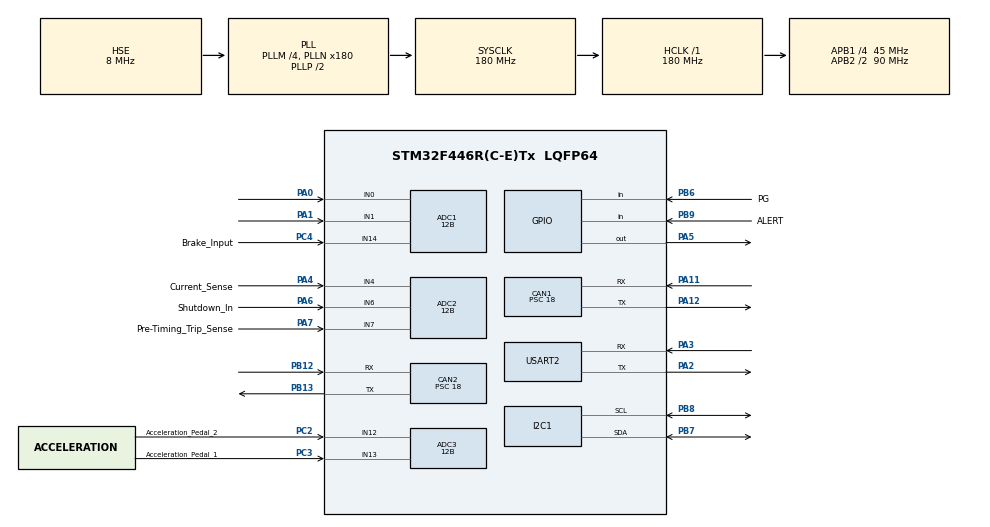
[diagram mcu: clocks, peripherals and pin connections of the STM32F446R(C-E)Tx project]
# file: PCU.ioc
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ADC1.Channel-0\#ChannelRegularConversion=ADC_CHANNEL_0
ADC1.Channel-1\#ChannelRegularConversion=ADC_CHANNEL_1
ADC1.Channel-2\#ChannelRegularConversion=ADC_CHANNEL_14
ADC1.ClockPrescaler=ADC_CLOCK_SYNC_PCLK_DIV4
ADC1.ContinuousConvMode=DISABLE
ADC1.DMAContinuousRequests=ENABLE
ADC1.DataAlign=ADC_DATAALIGN_RIGHT
ADC1.DiscontinuousConvMode=DISABLE
ADC1.EOCSelection=ADC_EOC_SEQ_CONV
ADC1.EnableAnalogWatchDog=false
ADC1.ExternalTrigConv=ADC_EXTERNALTRIGCONV_T2_TRGO
ADC1.ExternalTrigConvEdge=ADC_EXTERNALTRIGCONVEDGE_RISING
ADC1.NbrOfConversion=3
ADC1.NbrOfConversionFlag=1
ADC1.Rank-0\#ChannelRegularConversion=1
ADC1.Rank-1\#ChannelRegularConversion=2
ADC1.Rank-2\#ChannelRegularConversion=3
ADC1.Resolution=ADC_RESOLUTION_12B
ADC1.SamplingTime-0\#ChannelRegularConversion=ADC_SAMPLETIME_15CYCLES
ADC1.SamplingTime-1\#ChannelRegularConversion=ADC_SAMPLETIME_15CYCLES
ADC1.SamplingTime-2\#ChannelRegularConversion=ADC_SAMPLETIME_15CYCLES
ADC1.ScanConvMode=ENABLE
ADC1.master=1
ADC2.Channel-0\#ChannelRegularConversion=ADC_CHANNEL_4
ADC2.Channel-1\#ChannelRegularConversion=ADC_CHANNEL_6
ADC2.Channel-2\#ChannelRegularConversion=ADC_CHANNEL_7
ADC2.ClockPrescaler=ADC_CLOCK_SYNC_PCLK_DIV4
ADC2.ContinuousConvMode=DISABLE
ADC2.DMAContinuousRequests=ENABLE
ADC2.DataAlign=ADC_DATAALIGN_RIGHT
ADC2.DiscontinuousConvMode=DISABLE
ADC2.EOCSelection=ADC_EOC_SEQ_CONV
ADC2.EnableAnalogWatchDog=false
ADC2.ExternalTrigConv=ADC_EXTERNALTRIGCONV_T2_TRGO
ADC2.ExternalTrigConvEdge=ADC_EXTERNALTRIGCONVEDGE_RISING
ADC2.NbrOfConversion=3
ADC2.NbrOfConversionFlag=1
ADC2.Rank-0\#ChannelRegularConversion=1
ADC2.Rank-1\#ChannelRegularConversion=2
ADC2.Rank-2\#ChannelRegularConversion=3
ADC2.Resolution=ADC_RESOLUTION_12B
ADC2.SamplingTime-0\#ChannelRegularConversion=ADC_SAMPLETIME_15CYCLES
ADC2.SamplingTime-1\#ChannelRegularConversion=ADC_SAMPLETIME_15CYCLES
ADC2.SamplingTime-2\#ChannelRegularConversion=ADC_SAMPLETIME_15CYCLES
ADC2.ScanConvMode=ENABLE
ADC3.Channel-0\#ChannelRegularConversion=ADC_CHANNEL_1
ADC3.Channel-1\#ChannelRegularConversion=ADC_CHANNEL_0
ADC3.Channel-2\#ChannelRegularConversion=ADC_CHANNEL_12
ADC3.Channel-3\#ChannelRegularConversion=ADC_CHANNEL_13
ADC3.ClockPrescaler=ADC_CLOCK_SYNC_PCLK_DIV4
ADC3.ContinuousConvMode=DISABLE
ADC3.DMAContinuousRequests=ENABLE
ADC3.DataAlign=ADC_DATAALIGN_RIGHT
ADC3.DiscontinuousConvMode=DISABLE
ADC3.EOCSelection=ADC_EOC_SEQ_CONV
ADC3.EnableAnalogWatchDog=false
ADC3.ExternalTrigConv=ADC_EXTERNALTRIGCONV_T2_TRGO
ADC3.ExternalTrigConvEdge=ADC_EXTERNALTRIGCONVEDGE_RISING
ADC3.NbrOfConversion=4
ADC3.NbrOfConversionFlag=1
ADC3.Rank-0\#ChannelRegularConversion=1
ADC3.Rank-1\#ChannelRegularConversion=2
ADC3.Rank-2\#ChannelRegularConversion=3
ADC3.Rank-3\#ChannelRegularConversion=4
ADC3.Resolution=ADC_RESOLUTION_12B
ADC3.SamplingTime-0\#ChannelRegularConversion=ADC_SAMPLETIME_15CYCLES
ADC3.SamplingTime-1\#ChannelRegularConversion=ADC_SAMPLETIME_15CYCLES
ADC3.SamplingTime-2\#ChannelRegularConversion=ADC_SAMPLETIME_15CYCLES
ADC3.SamplingTime-3\#ChannelRegularConversion=ADC_SAMPLETIME_15CYCLES
ADC3.ScanConvMode=ENABLE
CAN1.BS1=CAN_BS1_3TQ
CAN1.CalculateBaudRate=500000
CAN1.CalculateTimeBit=2000
CAN1.CalculateTimeQuantum=400.0
CAN1.Mode=CAN_MODE_NORMAL
CAN1.Prescaler=18
CAN2.BS1=CAN_BS1_3TQ
CAN2.CalculateBaudRate=500000
CAN2.CalculateTimeBit=2000
CAN2.CalculateTimeQuantum=400.0
CAN2.Mode=CAN_MODE_NORMAL
CAN2.Prescaler=18
Dma.ADC1.0.Direction=DMA_PERIPH_TO_MEMORY
Dma.ADC1.0.FIFOMode=DMA_FIFOMODE_DISABLE
Dma.ADC1.0.Instance=DMA2_Stream0
Dma.ADC1.0.MemDataAlignment=DMA_MDATAALIGN_HALFWORD
Dma.ADC1.0.MemInc=DMA_MINC_ENABLE
Dma.ADC1.0.Mode=DMA_CIRCULAR
Dma.ADC1.0.PeriphDataAlignment=DMA_PDATAALIGN_HALFWORD
Dma.ADC1.0.PeriphInc=DMA_PINC_DISABLE
Dma.ADC1.0.Priority=DMA_PRIORITY_HIGH
Dma.ADC2.1.Direction=DMA_PERIPH_TO_MEMORY
Dma.ADC2.1.FIFOMode=DMA_FIFOMODE_DISABLE
Dma.ADC2.1.Instance=DMA2_Stream2
Dma.ADC2.1.MemDataAlignment=DMA_MDATAALIGN_HALFWORD
Dma.ADC2.1.MemInc=DMA_MINC_ENABLE
Dma.ADC2.1.Mode=DMA_CIRCULAR
Dma.ADC2.1.PeriphDataAlignment=DMA_PDATAALIGN_HALFWORD
Dma.ADC2.1.PeriphInc=DMA_PINC_DISABLE
Dma.ADC2.1.Priority=DMA_PRIORITY_HIGH
Dma.ADC3.2.Direction=DMA_PERIPH_TO_MEMORY
Dma.ADC3.2.FIFOMode=DMA_FIFOMODE_DISABLE
Dma.ADC3.2.Instance=DMA2_Stream1
Dma.ADC3.2.MemDataAlignment=DMA_MDATAALIGN_HALFWORD
Dma.ADC3.2.MemInc=DMA_MINC_ENABLE
Dma.ADC3.2.Mode=DMA_CIRCULAR
Dma.ADC3.2.PeriphDataAlignment=DMA_PDATAALIGN_HALFWORD
Dma.ADC3.2.PeriphInc=DMA_PINC_DISABLE
Dma.ADC3.2.Priority=DMA_PRIORITY_HIGH
Dma.Request0=ADC1
Dma.Request1=ADC2
Dma.Request2=ADC3
Dma.Request3=USART2_TX
Dma.Request4=USART2_RX
Dma.USART2_RX.4.Direction=DMA_PERIPH_TO_MEMORY
Dma.USART2_RX.4.FIFOMode=DMA_FIFOMODE_DISABLE
Dma.USART2_RX.4.Instance=DMA1_Stream5
Dma.USART2_RX.4.MemDataAlignment=DMA_MDATAALIGN_BYTE
Dma.USART2_RX.4.MemInc=DMA_MINC_ENABLE
Dma.USART2_RX.4.Mode=DMA_CIRCULAR
Dma.USART2_RX.4.PeriphDataAlignment=DMA_PDATAALIGN_BYTE
Dma.USART2_RX.4.PeriphInc=DMA_PINC_DISABLE
Dma.USART2_RX.4.Priority=DMA_PRIORITY_LOW
Dma.USART2_TX.3.Direction=DMA_MEMORY_TO_PERIPH
Dma.USART2_TX.3.FIFOMode=DMA_FIFOMODE_DISABLE
Dma.USART2_TX.3.Instance=DMA1_Stream6
Dma.USART2_TX.3.MemDataAlignment=DMA_MDATAALIGN_BYTE
Dma.USART2_TX.3.MemInc=DMA_MINC_ENABLE
Dma.USART2_TX.3.Mode=DMA_NORMAL
Dma.USART2_TX.3.PeriphDataAlignment=DMA_PDATAALIGN_BYTE
Dma.USART2_TX.3.PeriphInc=DMA_PINC_DISABLE
Dma.USART2_TX.3.Priority=DMA_PRIORITY_LOW
FREERTOS.CountingSemaphores01=canTxMailboxSem,3,Dynamic,NULL,3
FREERTOS.Mutexes01=canTxMutex,Dynamic,NULL,Available;i2cMutex,Dynamic,NULL,Available;canRxMutex,Dynamic,NULL,Available;logMutex,Dynamic,NULL,Available;uartTxMutex,Dynamic,NULL,Available
FREERTOS.Queues01=canTxQueue,16,FEB_CAN_Message_t,0,Dynamic,NULL,NULL;canRxQueue,32,FEB_CAN_Message_t,0,Dynamic,NULL,NULL;uartRxQueue,8,FEB_UART_RxQueueMsg_t,0,Dynamic,NULL,NULL
FREERTOS.Tasks01=pcuTask,24,512,StartPCUTask,As weak,NULL,Dynamic,NULL,NULL;uartRxTask,24,512,StartUartRxTask,As weak,NULL,Dynamic,NULL,NULL;canRxTask,40,1024,StartCanRxTask,As weak,NULL,Dynamic,NULL,NULL;canTxTask,40,1024,StartCanTxTask,As weak,NULL,Dynamic,NULL,NULL;canPubTask,40,512,StartCanPubTask,As weak,NULL,Dynamic,NULL,NULL
FREERTOS.configTOTAL_HEAP_SIZE=32768
Mcu.Family=STM32F4
Mcu.Name=STM32F446R(C-E)Tx
Mcu.Package=LQFP64
NVIC.ADC_IRQn=true\:5\:0\:false\:false\:true\:true\:true\:true\:true
NVIC.CAN1_RX0_IRQn=true\:5\:0\:false\:false\:true\:true\:true\:true\:true
NVIC.CAN1_RX1_IRQn=true\:5\:0\:false\:false\:true\:true\:true\:true\:true
NVIC.CAN1_SCE_IRQn=true\:5\:0\:false\:false\:true\:true\:true\:true\:true
NVIC.CAN1_TX_IRQn=true\:5\:0\:false\:false\:true\:true\:true\:true\:true
NVIC.CAN2_RX0_IRQn=true\:5\:0\:false\:false\:true\:true\:true\:true\:true
NVIC.CAN2_RX1_IRQn=true\:5\:0\:false\:false\:true\:true\:true\:true\:true
NVIC.CAN2_SCE_IRQn=true\:5\:0\:false\:false\:true\:true\:true\:true\:true
NVIC.CAN2_TX_IRQn=true\:5\:0\:false\:false\:true\:true\:true\:true\:true
NVIC.DMA1_Stream5_IRQn=true\:5\:0\:false\:false\:true\:true\:false\:true\:true
NVIC.DMA1_Stream6_IRQn=true\:5\:0\:false\:false\:true\:true\:false\:true\:true
NVIC.DMA2_Stream0_IRQn=true\:5\:0\:false\:false\:true\:true\:true\:true\:true
NVIC.DMA2_Stream1_IRQn=true\:5\:0\:false\:false\:true\:true\:true\:true\:true
NVIC.DMA2_Stream2_IRQn=true\:5\:0\:false\:false\:true\:true\:true\:true\:true
NVIC.PriorityGroup=NVIC_PRIORITYGROUP_4
NVIC.TIM1_UP_TIM10_IRQn=true\:5\:0\:false\:false\:true\:true\:true\:true\:true
NVIC.USART2_IRQn=true\:5\:0\:false\:false\:true\:true\:true\:true\:true
PA0-WKUP.Signal=ADCx_IN0
PA1.Signal=ADCx_IN1
PA11.Mode=CAN_Activate
PA11.Signal=CAN1_RX
PA12.Mode=CAN_Activate
PA12.Signal=CAN1_TX
PA13.Mode=JTAG_5_pins
PA13.Signal=SYS_JTMS-SWDIO
PA14.Mode=JTAG_5_pins
PA14.Signal=SYS_JTCK-SWCLK
PA15.Mode=JTAG_5_pins
PA15.Signal=SYS_JTDI
PA2.Mode=Asynchronous
PA2.Signal=USART2_TX
PA3.Mode=Asynchronous
PA3.Signal=USART2_RX
PA4.GPIO_Label=Current_Sense
PA4.Signal=ADCx_IN4
PA5.Signal=GPIO_Output
PA6.GPIO_Label=Shutdown_In
PA6.Signal=ADCx_IN6
PA7.GPIO_Label=Pre-Timing_Trip_Sense
PA7.Signal=ADCx_IN7
PB12.Mode=CAN_Activate
PB12.Signal=CAN2_RX
PB13.Mode=CAN_Activate
PB13.Signal=CAN2_TX
PB3.Mode=JTAG_5_pins
PB3.Signal=SYS_JTDO-SWO
PB4.Mode=JTAG_5_pins
PB4.Signal=SYS_JTRST
PB6.GPIO_Label=PG
PB6.Signal=GPIO_Input
PB7.Mode=I2C
PB7.Signal=I2C1_SDA
PB8.Mode=I2C
PB8.Signal=I2C1_SCL
PB9.GPIO_Label=ALERT
PB9.Signal=GPIO_Input
PC0.GPIO_Label=BSPD_Indicator
PC0.Signal=ADCx_IN10
PC1.GPIO_Label=BSPD_Reset
PC1.Signal=ADCx_IN11
PC2.GPIO_Label=Acceleration_Pedal_2
PC2.Signal=ADCx_IN12
PC3.GPIO_Label=Acceleration_Pedal_1
PC3.Signal=ADCx_IN13
PC4.GPIO_Label=Brake_Input
PC4.Signal=ADCx_IN14
PH0-OSC_IN.Mode=HSE-External-Oscillator
PH0-OSC_IN.Signal=RCC_OSC_IN
PH1-OSC_OUT.Mode=HSE-External-Oscillator
PH1-OSC_OUT.Signal=RCC_OSC_OUT
ProjectManager.HeapSize=0x200
ProjectManager.StackSize=0x400
ProjectManager.TargetToolchain=CMake
RCC.AHBFreq_Value=180000000
RCC.APB1CLKDivider=RCC_HCLK_DIV4
RCC.APB1Freq_Value=45000000
RCC.APB1TimFreq_Value=90000000
RCC.APB2CLKDivider=RCC_HCLK_DIV2
RCC.APB2Freq_Value=90000000
RCC.APB2TimFreq_Value=180000000
RCC.CortexFreq_Value=180000000
RCC.HCLKFreq_Value=180000000
RCC.HSE_VALUE=8000000
RCC.PLLM=4
RCC.PLLN=180
RCC.PLLSourceVirtual=RCC_PLLSOURCE_HSE
RCC.SYSCLKFreq_VALUE=180000000
RCC.SYSCLKSource=RCC_SYSCLKSOURCE_PLLCLK
RCC.USBFreq_Value=180000000
RCC.VCOOutputFreq_Value=360000000
SH.ADCx_IN0.0=ADC1_IN0,IN0
SH.ADCx_IN0.1=ADC3_IN0,IN0
SH.ADCx_IN1.0=ADC1_IN1,IN1
SH.ADCx_IN1.1=ADC3_IN1,IN1
SH.ADCx_IN10.0=ADC3_IN10
SH.ADCx_IN11.0=ADC3_IN11
SH.ADCx_IN12.0=ADC3_IN12,IN12
SH.ADCx_IN13.0=ADC3_IN13,IN13
SH.ADCx_IN14.0=ADC1_IN14,IN14
SH.ADCx_IN4.0=ADC2_IN4,IN4
SH.ADCx_IN6.0=ADC2_IN6,IN6
SH.ADCx_IN7.0=ADC2_IN7,IN7
TIM1.AutoReloadPreload=TIM_AUTORELOAD_PRELOAD_ENABLE
TIM1.Period=1000
TIM1.Prescaler=180
TIM2.AutoReloadPreload=TIM_AUTORELOAD_PRELOAD_ENABLE
TIM2.Period=99
TIM2.Prescaler=89
TIM2.TIM_MasterOutputTrigger=TIM_TRGO_UPDATE
USART2.VirtualMode=VM_ASYNC
VP_FREERTOS_VS_CMSIS_V2.Mode=CMSIS_V2
VP_TIM1_VS_ClockSourceINT.Mode=Internal
VP_TIM2_VS_ClockSourceINT.Mode=Internal
board=custom

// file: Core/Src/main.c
/* USER CODE BEGIN Header */
/**
  ******************************************************************************
  * @file           : main.c
  * @brief          : Main program body
  ******************************************************************************
  * @attention
  *
  * Copyright (c) 2026 STMicroelectronics.
  * All rights reserved.
  *
  * This software is licensed under terms that can be found in the LICENSE file
  * in the root directory of this software component.
  * If no LICENSE file comes with this software, it is provided AS-IS.
  *
  ******************************************************************************
  */
/* USER CODE END Header */
#include "main.h"
#include "cmsis_os.h"
#include "adc.h"
#include "can.h"
#include "dma.h"
#include "i2c.h"
#include "tim.h"
#include "usart.h"
#include "gpio.h"

/* USER CODE BEGIN Includes */
#include "PCU_Main.h"
/* USER CODE END Includes */

void SystemClock_Config(void);
void MX_FREERTOS_Init(void);

int main(void)
{

  /* MCU Configuration--------------------------------------------------------*/

  /* Reset of all peripherals, Initializes the Flash interface and the Systick. */
  HAL_Init();

  /* Configure the system clock */
  SystemClock_Config();

  /* Initialize all configured peripherals */
  MX_GPIO_Init();
  MX_DMA_Init();
  MX_USART2_UART_Init();
  MX_ADC1_Init();
  MX_ADC2_Init();
  MX_ADC3_Init();
  MX_CAN1_Init();
  MX_I2C1_Init();
  MX_CAN2_Init();
  MX_TIM1_Init();
  MX_TIM2_Init();

  /* Init scheduler */
  osKernelInitialize();  /* Call init function for freertos objects (in cmsis_os2.c) */
  MX_FREERTOS_Init();

  /* Start scheduler */
  osKernelStart();

  /* We should never get here as control is now taken by the scheduler */

  /* Infinite loop */
  while (1)
  {

  }
}

void SystemClock_Config(void)
{
  RCC_OscInitTypeDef RCC_OscInitStruct = {0};
  RCC_ClkInitTypeDef RCC_ClkInitStruct = {0};

  /** Configure the main internal regulator output voltage
  */
  __HAL_RCC_PWR_CLK_ENABLE();
  __HAL_PWR_VOLTAGESCALING_CONFIG(PWR_REGULATOR_VOLTAGE_SCALE1);

  /** Initializes the RCC Oscillators according to the specified parameters
  * in the RCC_OscInitTypeDef structure.
  */
  RCC_OscInitStruct.OscillatorType = RCC_OSCILLATORTYPE_HSE;
  RCC_OscInitStruct.HSEState = RCC_HSE_ON;
  RCC_OscInitStruct.PLL.PLLState = RCC_PLL_ON;
  RCC_OscInitStruct.PLL.PLLSource = RCC_PLLSOURCE_HSE;
  RCC_OscInitStruct.PLL.PLLM = 4;
  RCC_OscInitStruct.PLL.PLLN = 180;
  RCC_OscInitStruct.PLL.PLLP = RCC_PLLP_DIV2;
  RCC_OscInitStruct.PLL.PLLQ = 2;
  RCC_OscInitStruct.PLL.PLLR = 2;
  if (HAL_RCC_OscConfig(&RCC_OscInitStruct) != HAL_OK)
  {
    Error_Handler();
  }

  /** Activate the Over-Drive mode
  */
  if (HAL_PWREx_EnableOverDrive() != HAL_OK)
  {
    Error_Handler();
  }

  /** Initializes the CPU, AHB and APB buses clocks
  */
  RCC_ClkInitStruct.ClockType = RCC_CLOCKTYPE_HCLK|RCC_CLOCKTYPE_SYSCLK
                              |RCC_CLOCKTYPE_PCLK1|RCC_CLOCKTYPE_PCLK2;
  RCC_ClkInitStruct.SYSCLKSource = RCC_SYSCLKSOURCE_PLLCLK;
  RCC_ClkInitStruct.AHBCLKDivider = RCC_SYSCLK_DIV1;
  RCC_ClkInitStruct.APB1CLKDivider = RCC_HCLK_DIV4;
  RCC_ClkInitStruct.APB2CLKDivider = RCC_HCLK_DIV2;

  if (HAL_RCC_ClockConfig(&RCC_ClkInitStruct, FLASH_LATENCY_5) != HAL_OK)
  {
    Error_Handler();
  }
}

void Error_Handler(void)
{
  __disable_irq();
  while (1)
  {
  }
}

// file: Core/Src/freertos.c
/* USER CODE BEGIN Header */

/**
  ******************************************************************************
  * File Name          : freertos.c
  * Description        : Code for freertos applications
  ******************************************************************************
  * @attention
  *
  * Copyright (c) 2026 STMicroelectronics.
  * All rights reserved.
  *
  * This software is licensed under terms that can be found in the LICENSE file
  * in the root directory of this software component.
  * If no LICENSE file comes with this software, it is provided AS-IS.
  *
  ******************************************************************************
  */
/* USER CODE END Header */

#include "FreeRTOS.h"
#include "task.h"
#include "main.h"
#include "cmsis_os.h"

/* USER CODE BEGIN Includes */
#include "PCU_Main.h"
#include "feb_uart.h"
#include "feb_console.h"
#include "feb_can_lib.h"
#include <stdio.h>
/* USER CODE END Includes */

/* Definitions for pcuTask */
osThreadId_t pcuTaskHandle;
const osThreadAttr_t pcuTask_attributes = {
  .name = "pcuTask",
  .stack_size = 512 * 4,
  .priority = (osPriority_t) osPriorityNormal,
};
/* Definitions for uartRxTask */
osThreadId_t uartRxTaskHandle;
const osThreadAttr_t uartRxTask_attributes = {
  .name = "uartRxTask",
  .stack_size = 512 * 4,
  .priority = (osPriority_t) osPriorityNormal,
};
/* Definitions for canRxTask */
osThreadId_t canRxTaskHandle;
const osThreadAttr_t canRxTask_attributes = {
  .name = "canRxTask",
  .stack_size = 1024 * 4,
  .priority = (osPriority_t) osPriorityHigh,
};
/* Definitions for canTxTask */
osThreadId_t canTxTaskHandle;
const osThreadAttr_t canTxTask_attributes = {
  .name = "canTxTask",
  .stack_size = 1024 * 4,
  .priority = (osPriority_t) osPriorityHigh,
};
/* Definitions for canPubTask */
osThreadId_t canPubTaskHandle;
const osThreadAttr_t canPubTask_attributes = {
  .name = "canPubTask",
  .stack_size = 512 * 4,
  .priority = (osPriority_t) osPriorityHigh,
};
/* Definitions for canTxQueue */
osMessageQueueId_t canTxQueueHandle;
const osMessageQueueAttr_t canTxQueue_attributes = {
  .name = "canTxQueue"
};
/* Definitions for canRxQueue */
osMessageQueueId_t canRxQueueHandle;
const osMessageQueueAttr_t canRxQueue_attributes = {
  .name = "canRxQueue"
};
/* Definitions for uartRxQueue */
osMessageQueueId_t uartRxQueueHandle;
const osMessageQueueAttr_t uartRxQueue_attributes = {
  .name = "uartRxQueue"
};
/* Definitions for canTxMutex */
osMutexId_t canTxMutexHandle;
const osMutexAttr_t canTxMutex_attributes = {
  .name = "canTxMutex"
};
/* Definitions for i2cMutex */
osMutexId_t i2cMutexHandle;
const osMutexAttr_t i2cMutex_attributes = {
  .name = "i2cMutex"
};
/* Definitions for canRxMutex */
osMutexId_t canRxMutexHandle;
const osMutexAttr_t canRxMutex_attributes = {
  .name = "canRxMutex"
};
/* Definitions for logMutex */
osMutexId_t logMutexHandle;
const osMutexAttr_t logMutex_attributes = {
  .name = "logMutex"
};
/* Definitions for uartTxMutex */
osMutexId_t uartTxMutexHandle;
const osMutexAttr_t uartTxMutex_attributes = {
  .name = "uartTxMutex"
};
/* Definitions for canTxMailboxSem */
osSemaphoreId_t canTxMailboxSemHandle;
const osSemaphoreAttr_t canTxMailboxSem_attributes = {
  .name = "canTxMailboxSem"
};

void StartPCUTask(void *argument);
void StartUartRxTask(void *argument);
void StartCanRxTask(void *argument);
void StartCanTxTask(void *argument);
void StartCanPubTask(void *argument);

void MX_FREERTOS_Init(void); /* (MISRA C 2004 rule 8.1) */

void MX_FREERTOS_Init(void) {
  /* Create the mutex(es) */
  /* creation of canTxMutex */
  canTxMutexHandle = osMutexNew(&canTxMutex_attributes);

  /* creation of i2cMutex */
  i2cMutexHandle = osMutexNew(&i2cMutex_attributes);

  /* creation of canRxMutex */
  canRxMutexHandle = osMutexNew(&canRxMutex_attributes);

  /* creation of logMutex */
  logMutexHandle = osMutexNew(&logMutex_attributes);

  /* creation of uartTxMutex */
  uartTxMutexHandle = osMutexNew(&uartTxMutex_attributes);

  /* Create the semaphores(s) */
  /* creation of canTxMailboxSem */
  canTxMailboxSemHandle = osSemaphoreNew(3, 3, &canTxMailboxSem_attributes);

  /* Create the queue(s) */
  /* creation of canTxQueue */
  canTxQueueHandle = osMessageQueueNew (16, sizeof(FEB_CAN_Message_t), &canTxQueue_attributes);

  /* creation of canRxQueue */
  canRxQueueHandle = osMessageQueueNew (32, sizeof(FEB_CAN_Message_t), &canRxQueue_attributes);

  /* creation of uartRxQueue */
  uartRxQueueHandle = osMessageQueueNew (8, sizeof(FEB_UART_RxQueueMsg_t), &uartRxQueue_attributes);

  /* Create the thread(s) */
  /* creation of pcuTask */
  pcuTaskHandle = osThreadNew(StartPCUTask, NULL, &pcuTask_attributes);

  /* creation of uartRxTask */
  uartRxTaskHandle = osThreadNew(StartUartRxTask, NULL, &uartRxTask_attributes);

  /* creation of canRxTask */
  canRxTaskHandle = osThreadNew(StartCanRxTask, NULL, &canRxTask_attributes);

  /* creation of canTxTask */
  canTxTaskHandle = osThreadNew(StartCanTxTask, NULL, &canTxTask_attributes);

  /* creation of canPubTask */
  canPubTaskHandle = osThreadNew(StartCanPubTask, NULL, &canPubTask_attributes);

  /* USER CODE BEGIN RTOS_EVENTS */
  PCU_Init();
  /* USER CODE END RTOS_EVENTS */

}

__weak void StartPCUTask(void *argument)
{
  for(;;)
  {
    osDelay(1);
  }
}

__weak void StartUartRxTask(void *argument)
{
  for(;;)
  {
    osDelay(1);
  }
}

__weak void StartCanRxTask(void *argument)
{
  for(;;)
  {
    osDelay(1);
  }
}

__weak void StartCanTxTask(void *argument)
{
  for(;;)
  {
    osDelay(1);
  }
}

__weak void StartCanPubTask(void *argument)
{
  for(;;)
  {
    osDelay(1);
  }
}
